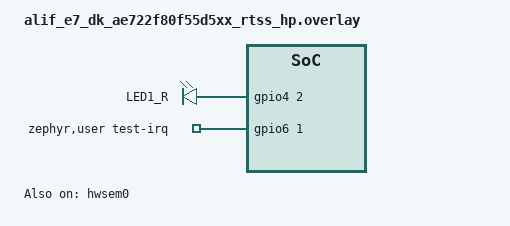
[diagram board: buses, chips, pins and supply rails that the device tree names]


/ {
	leds {
		compatible = "gpio-leds";

		aled0: led_0 {
			gpios = <&gpio4 2 0>;
			label = "LED1_R";
		};
	};

	zephyr,user {
		/* Test IRQ on P6.1 (same pin as HE, shared) */
		test-irq-gpios = <&gpio6 1 GPIO_ACTIVE_HIGH>;
	};
};

&hwsem0 {
	status = "okay";
};
&gpio6 {
	status = "okay";
};
&gpio4 {
	status = "ok";
};
